# AT32UC3A4256S device description
Architecture: AVR32_UC3; Family: AVR UC3
Registers are 32-bit, read-write, reset 0x0 unless marked. A register's access mark holds for its fields unless they carry their own. Offsets are from the block's base; [hi:lo] are bit positions; {n}, {i} and the like mark numbered series; 'fields as' and 'values as' point back to an identical list.

## RTC — Real Time Counter
Instances: RTC 0xffff0d00
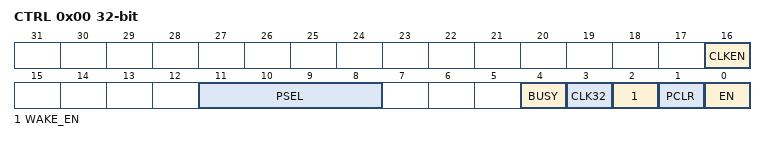
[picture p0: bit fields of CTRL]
0x00 CTRL — Real Time Counter Control
  [16] CLKEN — Clock enable
  [11:8] PSEL — Prescale Select
  [4] BUSY — Busy bit
  [3] CLK32 — Select 32KHz oscillator instead of RC Oscillator
  [2] WAKE_EN — Wake enable
  [1] PCLR — Prescaler Clear (strobe)
  [0] EN — Enable
0x04 VAL — RTC Value
0x08 TOP — RTC Top Value
  [31:0] VAL
0x10 IER wo — RTC Interrupt Enable Register
  [0] TOPI — TOP Interrupt
0x14 IDR wo — RTC Interrupt Disable Register
  [0] TOPI — TOP Interrupt
0x18 IMR ro — RTC Interrupt Mask Register
  [0] TOPI — TOP Interrupt
0x1C ISR ro — RTC Interrupt Status Register
  [0] TOPI — TOP Interrupt
0x20 ICR wo — RTC Interrupt Clear Register
  [0] TOPI — TOP Interrupt

## TWIM — Two-wire Master Interface
Instances: TWIM0 0xffff2c00, TWIM1 0xffff3000
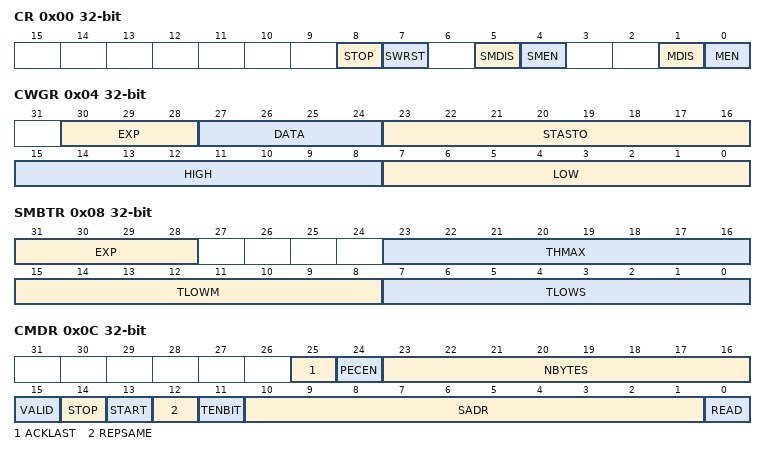
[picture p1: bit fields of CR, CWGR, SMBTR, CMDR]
0x00 CR wo
  [8] STOP, [7] SWRST, [5] SMDIS, [4] SMEN, [1] MDIS, [0] MEN
0x04 CWGR — Clock Waveform Generator
  [30:28] EXP, [27:24] DATA, [23:16] STASTO, [15:8] HIGH, [7:0] LOW
0x08 SMBTR — SMBus Time Out
  [31:28] EXP, [23:16] THMAX, [15:8] TLOWM, [7:0] TLOWS
0x0C CMDR — Command
  [25] ACKLAST, [24] PECEN, [23:16] NBYTES, [15] VALID, [14] STOP, [13] START, [12] REPSAME, [11] TENBIT, [10:1] SADR, [0] READ
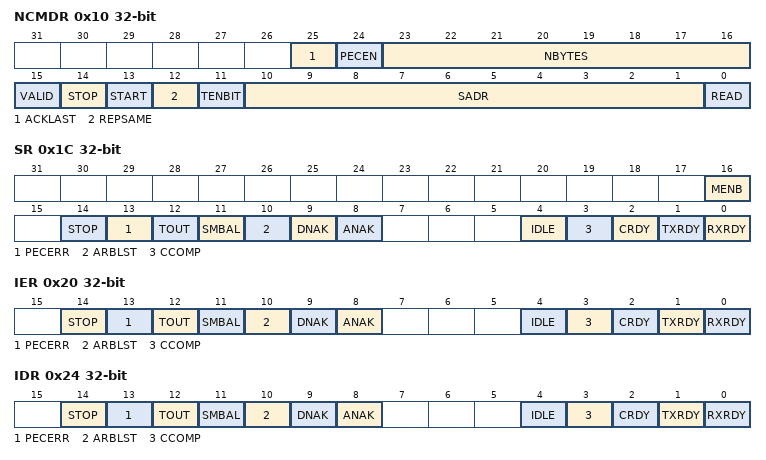
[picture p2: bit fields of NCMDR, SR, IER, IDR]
0x10 NCMDR — Next Command
  fields as CMDR
0x14 RHR ro — Receive Holding Registre
  [7:0] RXDATA
0x18 THR wo — Transmit Holding Register
  [7:0] TXDATA
0x1C SR ro — Status Register
  [16] MENB, [14] STOP, [13] PECERR, [12] TOUT, [11] SMBAL, [10] ARBLST, [9] DNAK, [8] ANAK, [4] IDLE, [3] CCOMP, [2] CRDY, [1] TXRDY, [0] RXRDY
0x20 IER wo — Interrupt Enable Register
  [14] STOP, [13] PECERR, [12] TOUT, [11] SMBAL, [10] ARBLST, [9] DNAK, [8] ANAK, [4] IDLE, [3] CCOMP, [2] CRDY, [1] TXRDY, [0] RXRDY
0x24 IDR wo — Interrupt Disable Register
  fields as IER
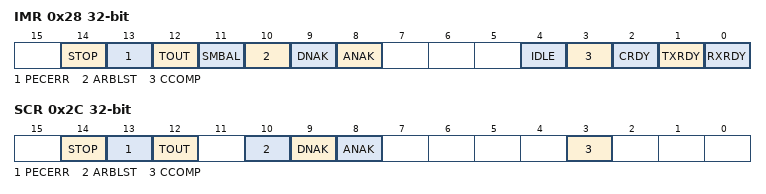
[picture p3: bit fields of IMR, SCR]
0x28 IMR ro — Interrupt Mask Register
  fields as IER
0x2C SCR wo — Status Clear Register
  [14] STOP, [13] PECERR, [12] TOUT, [10] ARBLST, [9] DNAK, [8] ANAK, [3] CCOMP
0x30 PR ro — Parameter Register
0x34 VR ro — Version Register
  [11:0] VERSION

## TWIS
Instances: TWIS0 0xffff5000, TWIS1 0xffff5400
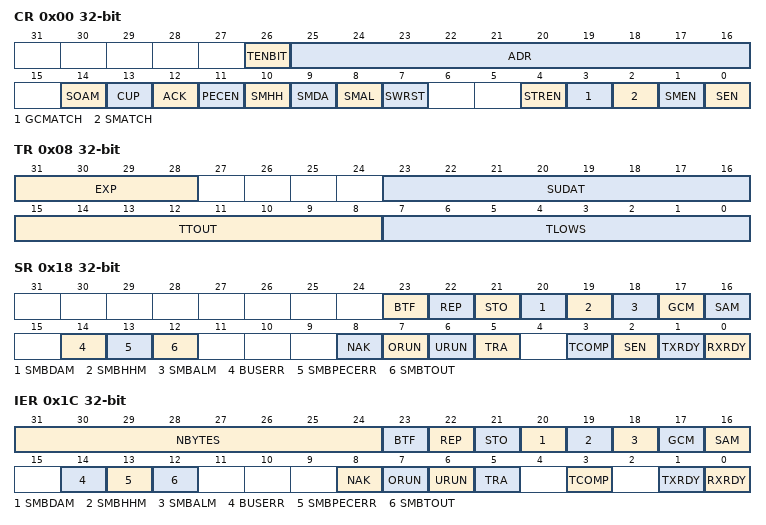
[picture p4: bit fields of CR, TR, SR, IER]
0x00 CR — Control Register
  [26] TENBIT, [25:16] ADR, [14] SOAM, [13] CUP, [12] ACK, [11] PECEN, [10] SMHH, [9] SMDA, [8] SMAL, [7] SWRST, [4] STREN, [3] GCMATCH, [2] SMATCH, [1] SMEN, [0] SEN
0x04 NBYTES
  [7:0] NBYTES
0x08 TR — Timing Register
  [31:28] EXP, [23:16] SUDAT, [15:8] TTOUT, [7:0] TLOWS
0x0C RHR ro — Receive Holding Registre
  [7:0] RXDATA
0x10 THR wo — Transmit Holding Register
  [7:0] TXDATA
0x14 PECR ro — Packet Error Check Register
  [7:0] PEC
0x18 SR ro — Status Register
  [23] BTF, [22] REP, [21] STO, [20] SMBDAM, [19] SMBHHM, [18] SMBALM, [17] GCM, [16] SAM, [14] BUSERR, [13] SMBPECERR, [12] SMBTOUT, [8] NAK, [7] ORUN, [6] URUN, [5] TRA, [3] TCOMP, [2] SEN, [1] TXRDY, [0] RXRDY
0x1C IER wo — Interrupt Enable Register
  [31:24] NBYTES, [23] BTF, [22] REP, [21] STO, [20] SMBDAM, [19] SMBHHM, [18] SMBALM, [17] GCM, [16] SAM, [14] BUSERR, [13] SMBPECERR, [12] SMBTOUT, [8] NAK, [7] ORUN, [6] URUN, [5] TRA, [3] TCOMP, [1] TXRDY, [0] RXRDY
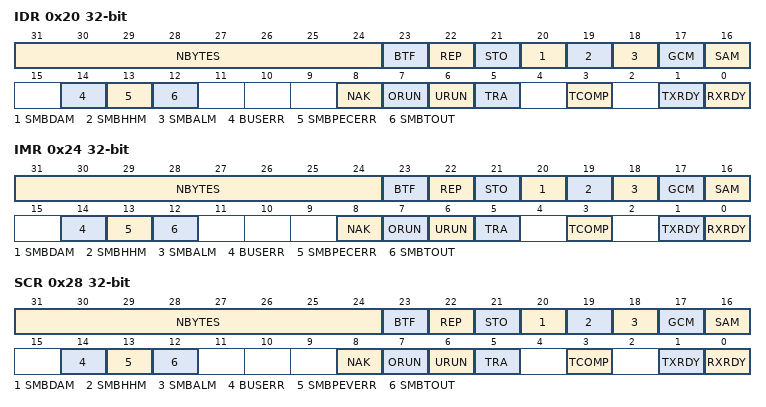
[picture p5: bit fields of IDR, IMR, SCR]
0x20 IDR wo — Interrupt Disable Register
  fields as IER
0x24 IMR ro — Interrupt Mask Register
  fields as IER
0x28 SCR — Interrupt Status Clear Register
  [31:24] NBYTES, [23] BTF, [22] REP, [21] STO, [20] SMBDAM, [19] SMBHHM, [18] SMBALM, [17] GCM, [16] SAM, [14] BUSERR, [13] SMBPEVERR, [12] SMBTOUT, [8] NAK, [7] ORUN, [6] URUN, [5] TRA, [3] TCOMP, [1] TXRDY, [0] RXRDY
0x2C PR ro — Parameter Register
0x30 VR ro — Version Register
  [7:0] VERSION

## WDT — Watchdog Timer
Instances: WDT 0xffff0d30
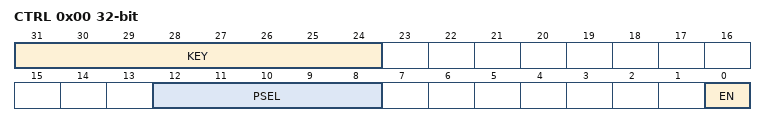
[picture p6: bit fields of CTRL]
0x00 CTRL — WDT Control
  [31:24] KEY
  [12:8] PSEL — Prescale Select
  [0] EN — WDT Enable
0x04 CLR wo — WDT Clear

## FLASH_FUSES — Fuses
Instances: FUSES 0xFFFE1400 in fuses
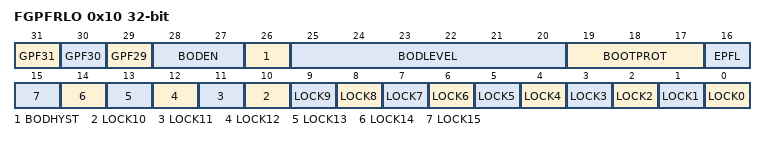
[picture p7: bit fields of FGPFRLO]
0x10 FGPFRLO reset not defined — Flash Controller General Purpose Fuse Register Low
  [31] GPF31 — General Purpose Fuse 31
  [30] GPF30 — General Purpose Fuse 30
  [29] GPF29 — General Purpose Fuse 29
  [28:27] BODEN — Brownout detector enable
    0=BOD_DISABLED; 1=BOD_ENABLED_RESET_ENABLED (BOD enabled, BOD reset enabled); 2=BOD_ENABLED_RESET_DISABLED (BOD enabled, BOD reset disabled); 3=BOD_DISABLED2
  [26] BODHYST — Brownout detector hysteresis
  [25:20] BODLEVEL — Brownout detector trigger level
    35=BOD_LEVEL_1V52 (BOD Level 1.52V); 31=BOD_LEVEL_1V61 (BOD Level 1.61V); 19=BOD_LEVEL_1V70 (BOD Level 1.70V); 15=BOD_LEVEL_1V52 (BOD Level 1.52V)
  [19:17] BOOTPROT — Bootloader protection
    0=BOOTAREA_64KB (Boot area: 64 Kbyte); 1=BOOTAREA_32KB (Boot area: 32 Kbyte); 2=BOOTAREA_16KB (Boot area: 16 Kbyte); 3=BOOTAREA_8KB (Boot area: 8 Kbyte); 4=BOOTAREA_4KB (Boot area: 4 Kbyte); 5=BOOTAREA_2KB (Boot area: 2 Kbyte); 6=BOOTAREA_1KB (Boot area: 1 Kbyte); 7=BOOTAREA_0B (Boot area: 0 byte)
  [16] EPFL — External privileged fetch lock
    0=EPFL_LOCK (External privileged fetch locked); 1=EPFL_NO_LOCK (External privileged fetch not locked)
  [n] LOCK{n} (n=0..15)
Value list SECURE: 0=SSDIS (Secure state disabled); 1=SSEN_SSDDIS (Secure enabled, secure state debug enabled); 2=SSEN_SSDEN (Secure enabled, secure state debug disabled); 3=SSDIS (Secure state disabled)
